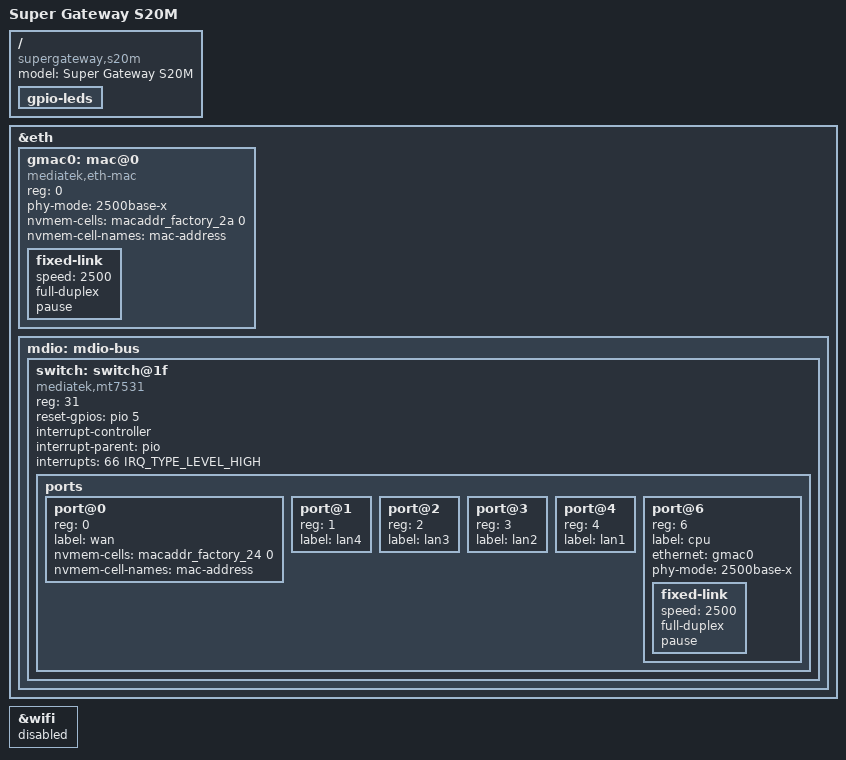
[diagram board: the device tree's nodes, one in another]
// SPDX-License-Identifier: GPL-2.0-or-later OR MIT

/dts-v1/;
#include "mt7986a-supergateway-s20-common.dtsi"

/ {
	model = "Super Gateway S20M";
	compatible = "supergateway,s20m", "mediatek,mt7986a";

	gpio-leds {
		/delete-node/ wlan5g_led;
		/delete-node/ wlan2g_led;
	};
};

&eth {
	status = "okay";

	gmac0: mac@0 {
		compatible = "mediatek,eth-mac";
		reg = <0>;
		phy-mode = "2500base-x";
		nvmem-cells = <&macaddr_factory_2a 0>;
		nvmem-cell-names = "mac-address";

		fixed-link {
			speed = <2500>;
			full-duplex;
			pause;
		};
	};

	mdio: mdio-bus {
		#address-cells = <1>;
		#size-cells = <0>;

		switch: switch@1f {
			compatible = "mediatek,mt7531";
			reg = <31>;
			reset-gpios = <&pio 5 GPIO_ACTIVE_HIGH>;
			interrupt-controller;
			#interrupt-cells = <1>;
			interrupt-parent = <&pio>;
			interrupts = <66 IRQ_TYPE_LEVEL_HIGH>;

			ports {
				#address-cells = <1>;
				#size-cells = <0>;

				port@0 {
					reg = <0>;
					label = "wan";

					nvmem-cells = <&macaddr_factory_24 0>;
					nvmem-cell-names = "mac-address";
				};

				port@1 {
					reg = <1>;
					label = "lan4";
				};

				port@2 {
					reg = <2>;
					label = "lan3";
				};

				port@3 {
					reg = <3>;
					label = "lan2";
				};

				port@4 {
					reg = <4>;
					label = "lan1";
				};

				port@6 {
					reg = <6>;
					label = "cpu";
					ethernet = <&gmac0>;
					phy-mode = "2500base-x";

					fixed-link {
						speed = <2500>;
						full-duplex;
						pause;
					};
				};
			};
		};
	};
};

&wifi {
	status = "disabled";
};
